AUTOSAR XML (schema 00048)
package /Eps_Repository/ActiveReturn/ActiveReturnCdp
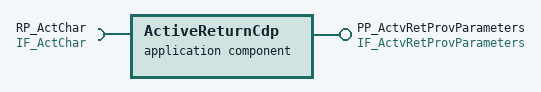
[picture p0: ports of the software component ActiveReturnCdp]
  application sw component type ActiveReturnCdp
    provide port PP_ActvRetProvParameters: provided-interface=IF_ActvRetProvParameters
    require port RP_ActChar: required-interface=IF_ActChar
    behavior IB_ActiveReturnCdp: constant-value-mapping=CSMS_ActvRetCdp, data-type-mapping=[DTMS_ActvRetCdp, DTMS_ActvRet_L_Adpr], handle-termination-and-restart=NO-SUPPORT
      13 x operation invoked event:
        OIE_ActiveReturnCdp_Prov_MaxMotTrqDepOnSteerAng: start-on-event=ActRetCdp_Prov_MaxMotTrqDepOnSteerAng, operation=PP_ActvRetProvParameters.Get_ActvRetMaxMotTrqDepOnSteerAng
        OIE_ActiveReturnCdp_Prov_MaxMotTrqDepOnVehSpd: start-on-event=ActRetCdp_Prov_MaxMotTrqDepOnVehSpd, operation=PP_ActvRetProvParameters.Get_ActvRetMaxMotTrqDepOnVehSpd
        OIE_ActiveReturnCdp_Prov_MaxMotTrq: start-on-event=ActRetCdp_Prov_MaxMotTrq, operation=PP_ActvRetProvParameters.Get_ActvRetMaxMotTrq
        OIE_ActiveReturnCdp_Prov_MaxTBT4ShtDwn: start-on-event=ActRetCdp_Prov_MaxTBT4ShtDwn, operation=PP_ActvRetProvParameters.Get_ActvRetMaxTBT4ShtDwn
        OIE_ActiveReturnCdp_Prov_NomSteerSpd: start-on-event=ActRetCdp_Prov_NomSteerSpd, operation=PP_ActvRetProvParameters.Get_ActvRetNomSteerSpd
        OIE_ActiveReturnCdp_Prov_FilFac: start-on-event=ActRetCdp_Prov_FilFac, operation=PP_ActvRetProvParameters.Get_ActvRetFilFac
        OIE_ActiveReturnCdp_Prov_MotTrqGain: start-on-event=ActRetCdp_Prov_MotTrqGain, operation=PP_ActvRetProvParameters.Get_ActvRetMotTrqGain
        OIE_ActiveReturnCdp_Prov_RetTrqFactDepOnDrvr: start-on-event=ActRetCdp_Prov_RetTrqFactDepOnDrvr, operation=PP_ActvRetProvParameters.Get_ActvRetRetTrqFactDepOnDrvr
        OIE_ActiveReturnCdp_Prov_SteerSpdFactDepOnDrvr: start-on-event=ActRetCdp_Prov_SteerSpdFactDepOnDrvr, operation=PP_ActvRetProvParameters.Get_ActvRetSteerSpdFactDepOnDrvr
        OIE_ActiveReturnCdp_Prov_SteerSpdGradAftInvld: start-on-event=ActRetCdp_Prov_SteerSpdGradAftInvld, operation=PP_ActvRetProvParameters.Get_ActvRetSteerSpdGradAftInvld
        OIE_ActiveReturnCdp_Prov_SteerSpdAmp: start-on-event=ActRetCdp_Prov_SteerSpdAmp, operation=PP_ActvRetProvParameters.Get_ActvRetSteerSpdAmp
        OIE_ActiveReturnCdp_Prov_SteerSpdFact: start-on-event=ActRetCdp_Prov_SteerSpdFact, operation=PP_ActvRetProvParameters.Get_ActvRetSteerSpdFact
        OIE_ActiveReturnCdp_Prov_MaxMotTrqAftLoadFac: start-on-event=ActRetCdp_Prov_MaxMotTrqAftLoadFac, operation=PP_ActvRetProvParameters.Get_ActvRetMaxMotTrqAftLoadFac
      13 x runnable:
        ActRetCdp_Prov_MaxMotTrqDepOnSteerAng: symbol=ActRetCdp_ProvideMaxMotorTorqueDepOnSteeringAngle
          data-receive-point-by-arguments:
            access DRP_RP_ActChar_ActChar: accessed-variable=RP_ActChar.ActChar
          6 x parameter access:
            SCPVA_MaxMotTrqDepOnSteerAngA: accessed-parameter=MaxMotTrqDepOnSteerAngA, sw-calprm-axis-set={sw-axis-index=1, sw-axis-grouped=ar-parameter=MaxMotTrqDepOnSteerAngA_AxisX}
            SCPVA_MaxMotTrqDepOnSteerAngA_AxisX: accessed-parameter=MaxMotTrqDepOnSteerAngA_AxisX
            SCPVA_MaxMotTrqDepOnSteerAngB_AxisX: accessed-parameter=MaxMotTrqDepOnSteerAngB_AxisX
            SCPVA_MaxMotTrqDepOnSteerAngC_AxisX: accessed-parameter=MaxMotTrqDepOnSteerAngC_AxisX
            SCPVA_MaxMotTrqDepOnSteerAngB: accessed-parameter=MaxMotTrqDepOnSteerAngB, sw-calprm-axis-set={sw-axis-index=1, sw-axis-grouped=ar-parameter=MaxMotTrqDepOnSteerAngB_AxisX}
            SCPVA_MaxMotTrqDepOnSteerAngC: accessed-parameter=MaxMotTrqDepOnSteerAngC, sw-calprm-axis-set={sw-axis-index=1, sw-axis-grouped=ar-parameter=MaxMotTrqDepOnSteerAngC_AxisX}
        ActRetCdp_Prov_MaxMotTrqDepOnVehSpd: symbol=ActRetCdp_ProvideMaxMotorTorqueDepOnVehSpeed
          data-receive-point-by-arguments:
            access DRP_RP_ActChar_ActChar: accessed-variable=RP_ActChar.ActChar
          6 x parameter access:
            SCPVA_MaxMotTrqDepOnVehSpdA: accessed-parameter=MaxMotTrqDepOnVehSpdA, sw-calprm-axis-set={sw-axis-index=1, sw-axis-grouped=ar-parameter=MaxMotTrqDepOnVehSpdA_AxisX}
            SCPVA_MaxMotTrqDepOnVehSpdA_AxisX: accessed-parameter=MaxMotTrqDepOnVehSpdA_AxisX
            SCPVA_MaxMotTrqDepOnVehSpdB_AxisX: accessed-parameter=MaxMotTrqDepOnVehSpdB_AxisX
            SCPVA_MaxMotTrqDepOnVehSpdC_AxisX: accessed-parameter=MaxMotTrqDepOnVehSpdC_AxisX
            SCPVA_MaxMotTrqDepOnVehSpdB: accessed-parameter=MaxMotTrqDepOnVehSpdB, sw-calprm-axis-set={sw-axis-index=1, sw-axis-grouped=ar-parameter=MaxMotTrqDepOnVehSpdB_AxisX}
            SCPVA_MaxMotTrqDepOnVehSpdC: accessed-parameter=MaxMotTrqDepOnVehSpdC, sw-calprm-axis-set={sw-axis-index=1, sw-axis-grouped=ar-parameter=MaxMotTrqDepOnVehSpdC_AxisX}
        ActRetCdp_Prov_MaxMotTrq: symbol=ActRetCdp_ProvideMaxMotorTorque
          data-receive-point-by-arguments:
            access DRP_RP_ActChar_ActChar: accessed-variable=RP_ActChar.ActChar
          parameter access SCPVA_MaxMotTrqA: accessed-parameter=MaxMotTrqA
          parameter access SCPVA_MaxMotTrqB: accessed-parameter=MaxMotTrqB
          parameter access SCPVA_MaxMotTrqC: accessed-parameter=MaxMotTrqC
        ActRetCdp_Prov_MaxTBT4ShtDwn: symbol=ActRetCdp_ProvideMaxTBT4ShutDown
          data-receive-point-by-arguments:
            access DRP_RP_ActChar_ActChar: accessed-variable=RP_ActChar.ActChar
          parameter access SCPVA_MaxTBT4ShtDwnA: accessed-parameter=MaxTBT4ShtDwnA
          parameter access SCPVA_MaxTBT4ShtDwnB: accessed-parameter=MaxTBT4ShtDwnB
          parameter access SCPVA_MaxTBT4ShtDwnC: accessed-parameter=MaxTBT4ShtDwnC
        ActRetCdp_Prov_NomSteerSpd: symbol=ActRetCdp_ProvideNominalSteeringSpeed
          data-receive-point-by-arguments:
            access DRP_RP_ActChar_ActChar: accessed-variable=RP_ActChar.ActChar
          9 x parameter access:
            SCPVA_NomSteerSpdA: accessed-parameter=NomSteerSpdA, sw-calprm-axis-set=[{sw-axis-index=1, sw-axis-grouped=ar-parameter=NomSteerSpdA_AxisX}, {sw-axis-index=2, sw-axis-grouped=ar-parameter=NomSteerSpdA_AxisY}]
            SCPVA_NomSteerSpdA_AxisX: accessed-parameter=NomSteerSpdA_AxisX
            SCPVA_NomSteerSpdA_AxisY: accessed-parameter=NomSteerSpdA_AxisY
            SCPVA_NomSteerSpdB_AxisX: accessed-parameter=NomSteerSpdB_AxisX
            SCPVA_NomSteerSpdB_AxisY: accessed-parameter=NomSteerSpdB_AxisY
            SCPVA_NomSteerSpdC_AxisX: accessed-parameter=NomSteerSpdC_AxisX
            SCPVA_NomSteerSpdC_AxisY: accessed-parameter=NomSteerSpdC_AxisY
            SCPVA_NomSteerSpdB: accessed-parameter=NomSteerSpdB, sw-calprm-axis-set=[{sw-axis-index=1, sw-axis-grouped=ar-parameter=NomSteerSpdB_AxisX}, {sw-axis-index=2, sw-axis-grouped=ar-parameter=NomSteerSpdB_AxisY}]
            SCPVA_NomSteerSpdC: accessed-parameter=NomSteerSpdC, sw-calprm-axis-set=[{sw-axis-index=1, sw-axis-grouped=ar-parameter=NomSteerSpdC_AxisX}, {sw-axis-index=2, sw-axis-grouped=ar-parameter=NomSteerSpdC_AxisY}]
        ActRetCdp_Prov_FilFac: symbol=ActRetCdp_ProvideFilterFactor
          data-receive-point-by-arguments:
            access DRP_RP_ActChar_ActChar: accessed-variable=RP_ActChar.ActChar
          parameter access SCPVA_FilFacA: accessed-parameter=FilFacA
          parameter access SCPVA_FilFacB: accessed-parameter=FilFacB
          parameter access SCPVA_FilFacC: accessed-parameter=FilFacC
        ActRetCdp_Prov_MotTrqGain: symbol=ActRetCdp_ProvideMotorTorqueGain
          data-receive-point-by-arguments:
            access DRP_RP_ActChar_ActChar: accessed-variable=RP_ActChar.ActChar
          6 x parameter access:
            SCPVA_MotTrqGainA: accessed-parameter=MotTrqGainA, sw-calprm-axis-set={sw-axis-index=1, sw-axis-grouped=ar-parameter=MotTrqGainA_AxisX}
            SCPVA_MotTrqGainA_AxisX: accessed-parameter=MotTrqGainA_AxisX
            SCPVA_MotTrqGainB_AxisX: accessed-parameter=MotTrqGainB_AxisX
            SCPVA_MotTrqGainC_AxisX: accessed-parameter=MotTrqGainC_AxisX
            SCPVA_MotTrqGainB: accessed-parameter=MotTrqGainB, sw-calprm-axis-set={sw-axis-index=1, sw-axis-grouped=ar-parameter=MotTrqGainB_AxisX}
            SCPVA_MotTrqGainC: accessed-parameter=MotTrqGainC, sw-calprm-axis-set={sw-axis-index=1, sw-axis-grouped=ar-parameter=MotTrqGainC_AxisX}
        ActRetCdp_Prov_RetTrqFactDepOnDrvr: symbol=ActRetCdp_ProvideRetTorqueFactDepOnDriver
          data-receive-point-by-arguments:
            access DRP_RP_ActChar_ActChar: accessed-variable=RP_ActChar.ActChar
          9 x parameter access:
            SCPVA_RetTrqFactDepOnDrvrA: accessed-parameter=RetTrqFactDepOnDrvrA, sw-calprm-axis-set=[{sw-axis-index=1, sw-axis-grouped=ar-parameter=RetTrqFactDepOnDrvrA_AxisX}, {sw-axis-index=2, sw-axis-grouped=ar-parameter=RetTrqFactDepOnDrvrA_AxisY}]
            SCPVA_RetTrqFactDepOnDrvrA_AxisX: accessed-parameter=RetTrqFactDepOnDrvrA_AxisX
            SCPVA_RetTrqFactDepOnDrvrA_AxisY: accessed-parameter=RetTrqFactDepOnDrvrA_AxisY
            SCPVA_RetTrqFactDepOnDrvrB_AxisX: accessed-parameter=RetTrqFactDepOnDrvrB_AxisX
            SCPVA_RetTrqFactDepOnDrvrB_AxisY: accessed-parameter=RetTrqFactDepOnDrvrB_AxisY
            SCPVA_RetTrqFactDepOnDrvrC_AxisX: accessed-parameter=RetTrqFactDepOnDrvrC_AxisX
            SCPVA_RetTrqFactDepOnDrvrC_AxisY: accessed-parameter=RetTrqFactDepOnDrvrC_AxisY
            SCPVA_RetTrqFactDepOnDrvrB: accessed-parameter=RetTrqFactDepOnDrvrB, sw-calprm-axis-set=[{sw-axis-index=1, sw-axis-grouped=ar-parameter=RetTrqFactDepOnDrvrB_AxisX}, {sw-axis-index=2, sw-axis-grouped=ar-parameter=RetTrqFactDepOnDrvrB_AxisY}]
            SCPVA_RetTrqFactDepOnDrvrC: accessed-parameter=RetTrqFactDepOnDrvrC, sw-calprm-axis-set=[{sw-axis-index=1, sw-axis-grouped=ar-parameter=RetTrqFactDepOnDrvrC_AxisX}, {sw-axis-index=2, sw-axis-grouped=ar-parameter=RetTrqFactDepOnDrvrC_AxisY}]
        ActRetCdp_Prov_SteerSpdFactDepOnDrvr: symbol=ActRetCdp_ProvideSteerSpeedFactDepOnDriver
          data-receive-point-by-arguments:
            access DRP_RP_ActChar_ActChar: accessed-variable=RP_ActChar.ActChar
          9 x parameter access:
            SCPVA_SteerSpdFactDepOnDrvrA: accessed-parameter=SteerSpdFactDepOnDrvrA, sw-calprm-axis-set=[{sw-axis-index=1, sw-axis-grouped=ar-parameter=SteerSpdFactDepOnDrvrA_AxisX}, {sw-axis-index=2, sw-axis-grouped=ar-parameter=SteerSpdFactDepOnDrvrA_AxisY}]
            SCPVA_SteerSpdFactDepOnDrvrA_AxisX: accessed-parameter=SteerSpdFactDepOnDrvrA_AxisX
            SCPVA_SteerSpdFactDepOnDrvrA_AxisY: accessed-parameter=SteerSpdFactDepOnDrvrA_AxisY
            SCPVA_SteerSpdFactDepOnDrvrB_AxisX: accessed-parameter=SteerSpdFactDepOnDrvrB_AxisX
            SCPVA_SteerSpdFactDepOnDrvrB_AxisY: accessed-parameter=SteerSpdFactDepOnDrvrB_AxisY
            SCPVA_SteerSpdFactDepOnDrvrC_AxisX: accessed-parameter=SteerSpdFactDepOnDrvrC_AxisX
            SCPVA_SteerSpdFactDepOnDrvrC_AxisY: accessed-parameter=SteerSpdFactDepOnDrvrC_AxisY
            SCPVA_SteerSpdFactDepOnDrvrB: accessed-parameter=SteerSpdFactDepOnDrvrB, sw-calprm-axis-set=[{sw-axis-index=1, sw-axis-grouped=ar-parameter=SteerSpdFactDepOnDrvrB_AxisX}, {sw-axis-index=2, sw-axis-grouped=ar-parameter=SteerSpdFactDepOnDrvrB_AxisY}]
            SCPVA_SteerSpdFactDepOnDrvrC: accessed-parameter=SteerSpdFactDepOnDrvrC, sw-calprm-axis-set=[{sw-axis-index=1, sw-axis-grouped=ar-parameter=SteerSpdFactDepOnDrvrC_AxisX}, {sw-axis-index=2, sw-axis-grouped=ar-parameter=SteerSpdFactDepOnDrvrC_AxisY}]
        ActRetCdp_Prov_SteerSpdGradAftInvld: symbol=ActRetCdp_ProvideSteerSpeedGradAfterInvalid
          data-receive-point-by-arguments:
            access DRP_RP_ActChar_ActChar: accessed-variable=RP_ActChar.ActChar
          parameter access SCPVA_SteerSpdGradAftInvldA: accessed-parameter=SteerSpdGradAftInvldA
          parameter access SCPVA_SteerSpdGradAftInvldB: accessed-parameter=SteerSpdGradAftInvldB
          parameter access SCPVA_SteerSpdGradAftInvldC: accessed-parameter=SteerSpdGradAftInvldC
        ActRetCdp_Prov_SteerSpdAmp: symbol=ActRetCdp_ProvideSteeringSpeedAmp
          data-receive-point-by-arguments:
            access DRP_RP_ActChar_ActChar: accessed-variable=RP_ActChar.ActChar
          parameter access SCPVA_SteerSpdAmpA: accessed-parameter=SteerSpdAmpA
          parameter access SCPVA_SteerSpdAmpB: accessed-parameter=SteerSpdAmpB
          parameter access SCPVA_SteerSpdAmpC: accessed-parameter=SteerSpdAmpC
        ActRetCdp_Prov_SteerSpdFact: symbol=ActRetCdp_ProvideSteeringSpeedFact
          data-receive-point-by-arguments:
            access DRP_RP_ActChar_ActChar: accessed-variable=RP_ActChar.ActChar
          parameter access SCPVA_SteerSpdFactA: accessed-parameter=SteerSpdFactA
          parameter access SCPVA_SteerSpdFactB: accessed-parameter=SteerSpdFactB
          parameter access SCPVA_SteerSpdFactC: accessed-parameter=SteerSpdFactC
        ActRetCdp_Prov_MaxMotTrqAftLoadFac: symbol=ActiveReturnCdp_ActRetCdp_Prov_MaxMotTrqAftLoadFac
          data-receive-point-by-arguments:
            access DRP_RP_ActChar_ActChar: accessed-variable=RP_ActChar.ActChar
          parameter access SCPVA_MaxMotTrqAftLoadFacA: accessed-parameter=MaxMotTrqAftLoadFacA
          parameter access SCPVA_MaxMotTrqAftLoadFacB: accessed-parameter=MaxMotTrqAftLoadFacB
          parameter access SCPVA_MaxMotTrqAftLoadFacC: accessed-parameter=MaxMotTrqAftLoadFacC
      shared-parameters:
        66 x parameter data prototype, all with sw-addr-method=CALIB, sw-calibration-access=READ-WRITE:
          MaxMotTrqDepOnSteerAngA_AxisX: unit=DegAngle, type=ADT_MaxMotTrqDepOnSteerAng_AxisX, init-value=constant-reference={short-label=ReferenceToConstant, constant=CS_MaxMotTrqDepOnSteerAng_AxisX}
          MaxMotTrqDepOnSteerAngB_AxisX: unit=DegAngle, type=ADT_MaxMotTrqDepOnSteerAng_AxisX, init-value=constant-reference={short-label=ReferenceToConstant, constant=CS_MaxMotTrqDepOnSteerAng_AxisX}
          MaxMotTrqDepOnSteerAngC_AxisX: unit=DegAngle, type=ADT_MaxMotTrqDepOnSteerAng_AxisX, init-value=constant-reference={short-label=ReferenceToConstant, constant=CS_MaxMotTrqDepOnSteerAng_AxisX}
          MaxMotTrqDepOnSteerAngA: sw-calprm-axis-set=sw-axis-grouped=ar-parameter=MaxMotTrqDepOnSteerAngA_AxisX, unit=NwtMtr, type=ADT_MaxMotTrqDepOnSteerAng, init-value=constant-reference={short-label=ReferenceToConstant, constant=CS_MaxMotTrqDepOnSteerAng}
          MaxMotTrqDepOnVehSpdA: sw-calprm-axis-set=sw-axis-grouped=ar-parameter=MaxMotTrqDepOnVehSpdA_AxisX, unit=NwtMtr, type=ADT_MaxMotTrqDepOnVehSpd, init-value=constant-reference={short-label=ReferenceToConstant, constant=CS_MaxMotTrqDepOnVehSpd}
          MaxMotTrqDepOnVehSpdA_AxisX: unit=KiloMtrPerHr, type=ADT_MaxMotTrqDepOnVehSpd_AxisX, init-value=constant-reference={short-label=ReferenceToConstant, constant=CS_MaxMotTrqDepOnVehSpd_AxisX}
          MaxMotTrqDepOnVehSpdB_AxisX: unit=KiloMtrPerHr, type=ADT_MaxMotTrqDepOnVehSpd_AxisX, init-value=constant-reference={short-label=ReferenceToConstant, constant=CS_MaxMotTrqDepOnVehSpd_AxisX}
          MaxMotTrqDepOnVehSpdC_AxisX: unit=KiloMtrPerHr, type=ADT_MaxMotTrqDepOnVehSpd_AxisX, init-value=constant-reference={short-label=ReferenceToConstant, constant=CS_MaxMotTrqDepOnVehSpd_AxisX}
          MotTrqGainA: sw-calprm-axis-set=sw-axis-grouped=ar-parameter=MotTrqGainA_AxisX, unit=NoUnit, type=ADT_MotTrqGain, init-value=constant-reference={short-label=ReferenceToConstant, constant=CS_MotTrqGain}
          MotTrqGainA_AxisX: unit=KiloMtrPerHr, type=ADT_MotTrqGain_AxisX, init-value=constant-reference={short-label=ReferenceToConstant, constant=CS_MotTrqGain_AxisX}
          MotTrqGainB_AxisX: unit=KiloMtrPerHr, type=ADT_MotTrqGain_AxisX, init-value=constant-reference={short-label=ReferenceToConstant, constant=CS_MotTrqGain_AxisX}
          MotTrqGainC_AxisX: unit=KiloMtrPerHr, type=ADT_MotTrqGain_AxisX, init-value=constant-reference={short-label=ReferenceToConstant, constant=CS_MotTrqGain_AxisX}
          RetTrqFactDepOnDrvrA: sw-calprm-axis-set=[{sw-axis-index=1, sw-axis-grouped=ar-parameter=RetTrqFactDepOnDrvrA_AxisX}, {sw-axis-index=2, sw-axis-grouped=ar-parameter=RetTrqFactDepOnDrvrA_AxisY}], unit=NoUnit, type=ADT_RetTrqFactDepOnDrvr, init-value=constant-reference={short-label=ReferenceToConstant, constant=CS_RetTrqFactDepOnDrvr}
          RetTrqFactDepOnDrvrA_AxisX: unit=NwtMtr, type=ADT_RetTrqFactDepOnDrvr_AxisX, init-value=constant-reference={short-label=ReferenceToConstant, constant=CS_RetTrqFactDepOnDrvr_AxisX}
          RetTrqFactDepOnDrvrB_AxisX: unit=NwtMtr, type=ADT_RetTrqFactDepOnDrvr_AxisX, init-value=constant-reference={short-label=ReferenceToConstant, constant=CS_RetTrqFactDepOnDrvr_AxisX}
          RetTrqFactDepOnDrvrC_AxisX: unit=NwtMtr, type=ADT_RetTrqFactDepOnDrvr_AxisX, init-value=constant-reference={short-label=ReferenceToConstant, constant=CS_RetTrqFactDepOnDrvr_AxisX}
          RetTrqFactDepOnDrvrA_AxisY: unit=KiloMtrPerHr, type=ADT_RetTrqFactDepOnDrvr_AxisY, init-value=constant-reference={short-label=ReferenceToConstant, constant=CS_RetTrqFactDepOnDrvr_AxisY}
          RetTrqFactDepOnDrvrB_AxisY: unit=KiloMtrPerHr, type=ADT_RetTrqFactDepOnDrvr_AxisY, init-value=constant-reference={short-label=ReferenceToConstant, constant=CS_RetTrqFactDepOnDrvr_AxisY}
          RetTrqFactDepOnDrvrC_AxisY: unit=KiloMtrPerHr, type=ADT_RetTrqFactDepOnDrvr_AxisY, init-value=constant-reference={short-label=ReferenceToConstant, constant=CS_RetTrqFactDepOnDrvr_AxisY}
          SteerSpdFactDepOnDrvrA: sw-calprm-axis-set=[{sw-axis-index=1, sw-axis-grouped=ar-parameter=SteerSpdFactDepOnDrvrA_AxisX}, {sw-axis-index=2, sw-axis-grouped=ar-parameter=SteerSpdFactDepOnDrvrA_AxisY}], unit=NoUnit, type=ADT_SteerSpdFactDepOnDrvr, init-value=constant-reference={short-label=ReferenceToConstant, constant=CS_SteerSpdFactDepOnDrvr}
          SteerSpdFactDepOnDrvrA_AxisX: unit=NwtMtr, type=ADT_SteerSpdFactDepOnDrvr_AxisX, init-value=constant-reference={short-label=ReferenceToConstant, constant=CS_SteerSpdFactDepOnDrvr_AxisX}
          SteerSpdFactDepOnDrvrB_AxisX: unit=NwtMtr, type=ADT_SteerSpdFactDepOnDrvr_AxisX, init-value=constant-reference={short-label=ReferenceToConstant, constant=CS_SteerSpdFactDepOnDrvr_AxisX}
          SteerSpdFactDepOnDrvrC_AxisX: unit=NwtMtr, type=ADT_SteerSpdFactDepOnDrvr_AxisX, init-value=constant-reference={short-label=ReferenceToConstant, constant=CS_SteerSpdFactDepOnDrvr_AxisX}
          SteerSpdFactDepOnDrvrA_AxisY: unit=KiloMtrPerHr, type=ADT_SteerSpdFactDepOnDrvr_AxisY, init-value=constant-reference={short-label=ReferenceToConstant, constant=CS_SteerSpdFactDepOnDrvr_AxisY}
          SteerSpdFactDepOnDrvrB_AxisY: unit=KiloMtrPerHr, type=ADT_SteerSpdFactDepOnDrvr_AxisY, init-value=constant-reference={short-label=ReferenceToConstant, constant=CS_SteerSpdFactDepOnDrvr_AxisY}
          SteerSpdFactDepOnDrvrC_AxisY: unit=KiloMtrPerHr, type=ADT_SteerSpdFactDepOnDrvr_AxisY, init-value=constant-reference={short-label=ReferenceToConstant, constant=CS_SteerSpdFactDepOnDrvr_AxisY}
          MaxMotTrqA: unit=NwtMtr, type=ADT_MaxMotTrq, init-value=constant-reference={short-label=ReferenceToConstant, constant=CS_MaxMotTrq}
          MaxTBT4ShtDwnA: unit=NwtMtr, type=ADT_MaxTBT4ShtDwn, init-value=constant-reference={short-label=ReferenceToConstant, constant=CS_MaxTBT4ShtDwn}
          FilFacA: unit=NoUnit, type=ADT_FilFac, init-value=constant-reference={short-label=ReferenceToConstant, constant=CS_FilFac}
          SteerSpdGradAftInvldA: unit=NoUnit, type=ADT_SteerSpdGradAftInvld, init-value=constant-reference={short-label=ReferenceToConstant, constant=CS_SteerSpdGradAftInvld}
          SteerSpdFactA: unit=NoUnit, type=ADT_SteerSpdFact, init-value=constant-reference={short-label=ReferenceToConstant, constant=CS_SteerSpdFact}
          NomSteerSpdA_AxisX: unit=KiloMtrPerHr, type=ADT_NomSteerSpd_AxisX, init-value=constant-reference={short-label=ReferenceToConstant, constant=CS_NomSteerSpd_AxisX}
          NomSteerSpdB_AxisX: unit=KiloMtrPerHr, type=ADT_NomSteerSpd_AxisX, init-value=constant-reference={short-label=ReferenceToConstant, constant=CS_NomSteerSpd_AxisX}
          NomSteerSpdC_AxisX: unit=KiloMtrPerHr, type=ADT_NomSteerSpd_AxisX, init-value=constant-reference={short-label=ReferenceToConstant, constant=CS_NomSteerSpd_AxisX}
          NomSteerSpdA_AxisY: unit=DegAngle, type=ADT_NomSteerSpd_AxisY, init-value=constant-reference={short-label=ReferenceToConstant, constant=CS_NomSteerSpd_AxisY}
          NomSteerSpdB_AxisY: unit=DegAngle, type=ADT_NomSteerSpd_AxisY, init-value=constant-reference={short-label=ReferenceToConstant, constant=CS_NomSteerSpd_AxisY}
          NomSteerSpdC_AxisY: unit=DegAngle, type=ADT_NomSteerSpd_AxisY, init-value=constant-reference={short-label=ReferenceToConstant, constant=CS_NomSteerSpd_AxisY}
          NomSteerSpdA: sw-calprm-axis-set=[{sw-axis-index=1, sw-axis-grouped=ar-parameter=NomSteerSpdA_AxisX}, {sw-axis-index=2, sw-axis-grouped=ar-parameter=NomSteerSpdA_AxisY}], unit=NoUnit, type=ADT_NomSteerSpd, init-value=constant-reference={short-label=ReferenceToConstant, constant=CS_NomSteerSpd}
          SteerSpdAmpA: unit=NoUnit, type=ADT_SteerSpdAmp, init-value=constant-reference={short-label=ReferenceToConstant, constant=CS_SteerSpdAmp}
          MaxMotTrqB: unit=NwtMtr, type=ADT_MaxMotTrq, init-value=constant-reference={short-label=ReferenceToConstant, constant=CS_MaxMotTrq}
          MaxMotTrqC: unit=NwtMtr, type=ADT_MaxMotTrq, init-value=constant-reference={short-label=ReferenceToConstant, constant=CS_MaxMotTrq}
          MaxMotTrqDepOnSteerAngB: sw-calprm-axis-set=sw-axis-grouped=ar-parameter=MaxMotTrqDepOnSteerAngB_AxisX, unit=NwtMtr, type=ADT_MaxMotTrqDepOnSteerAng, init-value=constant-reference={short-label=ReferenceToConstant, constant=CS_MaxMotTrqDepOnSteerAng}
          MaxMotTrqDepOnVehSpdB: sw-calprm-axis-set=sw-axis-grouped=ar-parameter=MaxMotTrqDepOnVehSpdB_AxisX, unit=NwtMtr, type=ADT_MaxMotTrqDepOnVehSpd, init-value=constant-reference={short-label=ReferenceToConstant, constant=CS_MaxMotTrqDepOnVehSpd}
          MaxTBT4ShtDwnB: unit=NwtMtr, type=ADT_MaxTBT4ShtDwn, init-value=constant-reference={short-label=ReferenceToConstant, constant=CS_MaxTBT4ShtDwn}
          MaxMotTrqDepOnSteerAngC: sw-calprm-axis-set=sw-axis-grouped=ar-parameter=MaxMotTrqDepOnSteerAngC_AxisX, unit=NwtMtr, type=ADT_MaxMotTrqDepOnSteerAng, init-value=constant-reference={short-label=ReferenceToConstant, constant=CS_MaxMotTrqDepOnSteerAng}
          MaxMotTrqDepOnVehSpdC: sw-calprm-axis-set=sw-axis-grouped=ar-parameter=MaxMotTrqDepOnVehSpdC_AxisX, unit=NwtMtr, type=ADT_MaxMotTrqDepOnVehSpd, init-value=constant-reference={short-label=ReferenceToConstant, constant=CS_MaxMotTrqDepOnVehSpd}
          MaxTBT4ShtDwnC: unit=NwtMtr, type=ADT_MaxTBT4ShtDwn, init-value=constant-reference={short-label=ReferenceToConstant, constant=CS_MaxTBT4ShtDwn}
          NomSteerSpdB: sw-calprm-axis-set=[{sw-axis-index=1, sw-axis-grouped=ar-parameter=NomSteerSpdB_AxisX}, {sw-axis-index=2, sw-axis-grouped=ar-parameter=NomSteerSpdB_AxisY}], unit=NoUnit, type=ADT_NomSteerSpd, init-value=constant-reference={short-label=ReferenceToConstant, constant=CS_NomSteerSpd}
          NomSteerSpdC: sw-calprm-axis-set=[{sw-axis-index=1, sw-axis-grouped=ar-parameter=NomSteerSpdC_AxisX}, {sw-axis-index=2, sw-axis-grouped=ar-parameter=NomSteerSpdC_AxisY}], unit=NoUnit, type=ADT_NomSteerSpd, init-value=constant-reference={short-label=ReferenceToConstant, constant=CS_NomSteerSpd}
          FilFacB: unit=NoUnit, type=ADT_FilFac, init-value=constant-reference={short-label=ReferenceToConstant, constant=CS_FilFac}
          FilFacC: unit=NoUnit, type=ADT_FilFac, init-value=constant-reference={short-label=ReferenceToConstant, constant=CS_FilFac}
          MotTrqGainB: sw-calprm-axis-set=sw-axis-grouped=ar-parameter=MotTrqGainB_AxisX, unit=NoUnit, type=ADT_MotTrqGain, init-value=constant-reference={short-label=ReferenceToConstant, constant=CS_MotTrqGain}
          MotTrqGainC: sw-calprm-axis-set=sw-axis-grouped=ar-parameter=MotTrqGainC_AxisX, unit=NoUnit, type=ADT_MotTrqGain, init-value=constant-reference={short-label=ReferenceToConstant, constant=CS_MotTrqGain}
          RetTrqFactDepOnDrvrB: sw-calprm-axis-set=[{sw-axis-index=1, sw-axis-grouped=ar-parameter=RetTrqFactDepOnDrvrB_AxisX}, {sw-axis-index=2, sw-axis-grouped=ar-parameter=RetTrqFactDepOnDrvrB_AxisY}], unit=NoUnit, type=ADT_RetTrqFactDepOnDrvr, init-value=constant-reference={short-label=ReferenceToConstant, constant=CS_RetTrqFactDepOnDrvr}
          RetTrqFactDepOnDrvrC: sw-calprm-axis-set=[{sw-axis-index=1, sw-axis-grouped=ar-parameter=RetTrqFactDepOnDrvrC_AxisX}, {sw-axis-index=2, sw-axis-grouped=ar-parameter=RetTrqFactDepOnDrvrC_AxisY}], unit=NoUnit, type=ADT_RetTrqFactDepOnDrvr, init-value=constant-reference={short-label=ReferenceToConstant, constant=CS_RetTrqFactDepOnDrvr}
          SteerSpdAmpB: unit=NoUnit, type=ADT_SteerSpdAmp, init-value=constant-reference={short-label=ReferenceToConstant, constant=CS_SteerSpdAmp}
          SteerSpdAmpC: unit=NoUnit, type=ADT_SteerSpdAmp, init-value=constant-reference={short-label=ReferenceToConstant, constant=CS_SteerSpdAmp}
          SteerSpdFactB: unit=NoUnit, type=ADT_SteerSpdFact, init-value=constant-reference={short-label=ReferenceToConstant, constant=CS_SteerSpdFact}
          SteerSpdFactC: unit=NoUnit, type=ADT_SteerSpdFact, init-value=constant-reference={short-label=ReferenceToConstant, constant=CS_SteerSpdFact}
          SteerSpdFactDepOnDrvrB: sw-calprm-axis-set=[{sw-axis-index=1, sw-axis-grouped=ar-parameter=SteerSpdFactDepOnDrvrB_AxisX}, {sw-axis-index=2, sw-axis-grouped=ar-parameter=SteerSpdFactDepOnDrvrB_AxisY}], unit=NoUnit, type=ADT_SteerSpdFactDepOnDrvr, init-value=constant-reference={short-label=ReferenceToConstant, constant=CS_SteerSpdFactDepOnDrvr}
          SteerSpdFactDepOnDrvrC: sw-calprm-axis-set=[{sw-axis-index=1, sw-axis-grouped=ar-parameter=SteerSpdFactDepOnDrvrC_AxisX}, {sw-axis-index=2, sw-axis-grouped=ar-parameter=SteerSpdFactDepOnDrvrC_AxisY}], unit=NoUnit, type=ADT_SteerSpdFactDepOnDrvr, init-value=constant-reference={short-label=ReferenceToConstant, constant=CS_SteerSpdFactDepOnDrvr}
          SteerSpdGradAftInvldB: unit=NoUnit, type=ADT_SteerSpdGradAftInvld, init-value=constant-reference={short-label=ReferenceToConstant, constant=CS_SteerSpdGradAftInvld}
          SteerSpdGradAftInvldC: unit=NoUnit, type=ADT_SteerSpdGradAftInvld, init-value=constant-reference={short-label=ReferenceToConstant, constant=CS_SteerSpdGradAftInvld}
          MaxMotTrqAftLoadFacA: unit=NwtMtr, type=ADT_MaxMotTrqAftLoadFac, init-value=constant-reference={short-label=ReferenceToConstant, constant=CS_MaxMotTrqAftLoadFac}
          MaxMotTrqAftLoadFacB: unit=NwtMtr, type=ADT_MaxMotTrqAftLoadFac, init-value=constant-reference={short-label=ReferenceToConstant, constant=CS_MaxMotTrqAftLoadFac}
          MaxMotTrqAftLoadFacC: unit=NwtMtr, type=ADT_MaxMotTrqAftLoadFac, init-value=constant-reference={short-label=ReferenceToConstant, constant=CS_MaxMotTrqAftLoadFac}
package /Eps_Repository/ActiveReturn/ActiveReturnCdp/ApplicationDataTypes
  35 x app type:
    ADT_NomSteerSpd: category=MAP, sw-addr-method=CALIB, sw-calibration-access=READ-WRITE, sw-calprm-axis-set=[{sw-axis-index=1, category=COM_AXIS, sw-axis-grouped=ADT_NomSteerSpd_AxisX}, {sw-axis-index=2, category=COM_AXIS, sw-axis-grouped=ADT_NomSteerSpd_AxisY}], compu-method=CM_SAS_8, range phys 0..1500, raw 0..12000, sw-record-layout=SwRecordLayout_Map_uint16
    ADT_NomSteerSpd_AxisX: category=COM_AXIS, sw-calibration-access=READ-WRITE, sw-calprm-axis-set={sw-axis-index=1, sw-axis-individual={input-variable-type=ADT_AbsAvgVehSpd, compu-method=CM_VFZHIGH, sw-max-axis-points=6, sw-min-axis-points=6, range phys 0..500, raw 0..32000}}, sw-record-layout=SwRecordLayout_Axis_uint16
    ADT_NomSteerSpd_AxisY: category=COM_AXIS, sw-calibration-access=READ-WRITE, sw-calprm-axis-set={sw-axis-index=2, sw-axis-individual={input-variable-type=ADT_AbsSteerAng, compu-method=CM_SA_10, sw-max-axis-points=13, sw-min-axis-points=13, range phys 0..1000, raw 0..10000}}, sw-record-layout=SwRecordLayout_Axis_uint16
    ADT_MaxTBT4ShtDwn: category=VALUE, compu-method=CM_TBT_RSH4, range phys 0..15, raw 0..240
    ADT_FilFac: category=VALUE, compu-method=CM_RIGHTSH10NP, range phys 0.01..1, raw 0..1024
    ADT_FilFac_Val: category=VALUE, compu-method=CM_RIGHTSH10NP, range phys 0.01..1, raw 0..1024
    ADT_MaxTBT4ShtDwn_Val: category=VALUE, compu-method=CM_TBT_RSH4, range phys 0..15, raw 0..240
    ADT_MaxMotTrqDepOnSteerAng_AxisX: category=COM_AXIS, sw-calibration-access=READ-WRITE, sw-calprm-axis-set={sw-axis-index=1, sw-axis-individual={input-variable-type=ADT_AbsSteerAng, compu-method=CM_SA_10, sw-max-axis-points=5, sw-min-axis-points=5, range phys 0..1000, raw 0..10000}}, sw-record-layout=SwRecordLayout_Axis_uint16
    ADT_MaxMotTrqDepOnSteerAng: category=CURVE, sw-addr-method=CALIB, sw-calibration-access=READ-WRITE, sw-calprm-axis-set={sw-axis-index=1, category=COM_AXIS, sw-axis-grouped=ADT_MaxMotTrqDepOnSteerAng_AxisX}, compu-method=CM_MMOT, range phys 0..3, raw 0..3072, sw-record-layout=SwRecordLayout_Curve_uint16
    ADT_MaxMotTrqDepOnVehSpd_Val: category=VALUE, compu-method=CM_MMOT, range phys 0..3, raw 0..3072
    ADT_NomSteerSpd_Val: category=VALUE, compu-method=CM_SAS_8, range phys 0..1500, raw 0..12000
    ADT_RetTrqFactDepOnDrvr_Val: category=VALUE, compu-method=CM_RIGHTSH10NP, range phys 0..1, raw 0..1024
    ADT_SteerSpdGradAftInvld: category=VALUE, compu-method=CM_RIGHTSH15NP, range phys 0..1, raw 0..32768
    ADT_SteerSpdGradAftInvld_Val: category=VALUE, compu-method=CM_RIGHTSH15NP, range phys 0..1, raw 0..32768
    ADT_SteerSpdAmp: category=VALUE, compu-method=CM_ARFACT, range phys 0..0.02, raw 0..328
    ADT_SteerSpdAmp_Val: category=VALUE, compu-method=CM_ARFACT, range phys 0..0.02, raw 0..328
    ADT_SteerSpdFact: category=VALUE, compu-method=CM_RIGHTSH7NP, range phys 0..1.5, raw 0..192
    ADT_SteerSpdFact_Val: category=VALUE, compu-method=CM_RIGHTSH7NP, range phys 0..1.5, raw 0..192
    ADT_MaxMotTrqDepOnVehSpd_AxisX: category=COM_AXIS, sw-calibration-access=READ-WRITE, sw-calprm-axis-set={sw-axis-index=1, sw-axis-individual={input-variable-type=ADT_AbsMaxSafeVehSpd, compu-method=CM_VFZHIGH, sw-max-axis-points=5, sw-min-axis-points=5, range phys 0..500, raw 0..32000}}, sw-record-layout=SwRecordLayout_Axis_uint16
    ADT_MaxMotTrqDepOnVehSpd: category=CURVE, sw-addr-method=CALIB, sw-calibration-access=READ-WRITE, sw-calprm-axis-set={sw-axis-index=1, category=COM_AXIS, sw-axis-grouped=ADT_MaxMotTrqDepOnVehSpd_AxisX}, compu-method=CM_MMOT, range phys 0..3, raw 0..3072, sw-record-layout=SwRecordLayout_Curve_uint16
    ADT_MaxMotTrqDepOnSteerAng_Val: category=VALUE, compu-method=CM_MMOT, range phys 0..3, raw 0..3072
    ADT_MotTrqGain_Val: category=VALUE, compu-method=CM_RIGHTSH10NP, range phys 0..3, raw 0..3072
    ADT_MotTrqGain: category=CURVE, sw-addr-method=CALIB, sw-calibration-access=READ-WRITE, sw-calprm-axis-set={sw-axis-index=1, category=COM_AXIS, sw-axis-grouped=ADT_MotTrqGain_AxisX}, compu-method=CM_RIGHTSH10NP, range phys 0..3, raw 0..3072, sw-record-layout=SwRecordLayout_Curve_uint16
    ADT_MotTrqGain_AxisX: category=COM_AXIS, sw-calibration-access=READ-WRITE, sw-calprm-axis-set={sw-axis-index=1, sw-axis-individual={input-variable-type=ADT_AbsAvgVehSpd, compu-method=CM_VFZHIGH, sw-max-axis-points=6, sw-min-axis-points=6, range phys 0..250, raw 0..16000}}, sw-record-layout=SwRecordLayout_Axis_uint16
    ADT_RetTrqFactDepOnDrvr: category=MAP, sw-addr-method=CALIB, sw-calibration-access=READ-WRITE, sw-calprm-axis-set=[{sw-axis-index=1, category=COM_AXIS, sw-axis-grouped=ADT_RetTrqFactDepOnDrvr_AxisX}, {sw-axis-index=2, category=COM_AXIS, sw-axis-grouped=ADT_RetTrqFactDepOnDrvr_AxisY}], compu-method=CM_RIGHTSH10NP, range phys 0..1, raw 0..1024, sw-record-layout=SwRecordLayout_Map_uint16
    ADT_RetTrqFactDepOnDrvr_AxisX: category=COM_AXIS, sw-calibration-access=READ-WRITE, sw-calprm-axis-set={sw-axis-index=1, sw-axis-individual={input-variable-type=ADT_AbsDrvrTrq, compu-method=CM_TBTHIGH, sw-max-axis-points=6, sw-min-axis-points=6, range phys 0..25, raw 0..25600}}, sw-record-layout=SwRecordLayout_Axis_uint16
    ADT_RetTrqFactDepOnDrvr_AxisY: category=COM_AXIS, sw-calibration-access=READ-WRITE, sw-calprm-axis-set={sw-axis-index=2, sw-axis-individual={input-variable-type=ADT_AbsAvgVehSpd, compu-method=CM_VFZHIGH, sw-max-axis-points=3, sw-min-axis-points=3, range phys 0..500, raw 0..32000}}, sw-record-layout=SwRecordLayout_Axis_uint16
    ADT_SteerSpdFactDepOnDrvr: category=MAP, sw-addr-method=CALIB, sw-calibration-access=READ-WRITE, sw-calprm-axis-set=[{sw-axis-index=1, category=COM_AXIS, sw-axis-grouped=ADT_SteerSpdFactDepOnDrvr_AxisX}, {sw-axis-index=2, category=COM_AXIS, sw-axis-grouped=ADT_SteerSpdFactDepOnDrvr_AxisY}], compu-method=CM_RIGHTSH10NP, range phys 0..1, raw 0..1024, sw-record-layout=SwRecordLayout_Map_uint16
    ADT_SteerSpdFactDepOnDrvr_AxisX: category=COM_AXIS, sw-calibration-access=READ-WRITE, sw-calprm-axis-set={sw-axis-index=1, sw-axis-individual={input-variable-type=ADT_AbsDrvrTrq, compu-method=CM_TBTHIGH, sw-max-axis-points=6, sw-min-axis-points=6, range phys 0..25, raw 0..25600}}, sw-record-layout=SwRecordLayout_Axis_uint16
    ADT_SteerSpdFactDepOnDrvr_AxisY: category=COM_AXIS, sw-calibration-access=READ-WRITE, sw-calprm-axis-set={sw-axis-index=2, sw-axis-individual={input-variable-type=ADT_AbsAvgVehSpd, compu-method=CM_VFZHIGH, sw-max-axis-points=3, sw-min-axis-points=3, range phys 0..500, raw 0..32000}}, sw-record-layout=SwRecordLayout_Axis_uint16
    ADT_SteerSpdFactDepOnDrvr_Val: category=VALUE, compu-method=CM_RIGHTSH10NP, range phys 0..1, raw 0..1024
    ADT_MaxMotTrq: category=VALUE, compu-method=CM_MMOT_RSH6, range phys 0..3, raw 0..192
    ADT_MaxMotTrq_Val: category=VALUE, compu-method=CM_MMOT_RSH6, range phys 0..3, raw 0..192
    ADT_MaxMotTrqAftLoadFac: category=VALUE, compu-method=CM_MMOT_RSH6, range phys 0..3, raw 0..192
    ADT_MaxMotTrqAftLoadFac_Val: category=VALUE, compu-method=CM_MMOT_RSH6, range phys 0..3, raw 0..192
package /Eps_Repository/ActiveReturn/ActiveReturnCdp/DataTypeMappingSets
  data type mapping set DTMS_ActvRetCdp
    data-type-maps:
      application-data-type=ADT_SteerSpdGradAftInvld, implementation-data-type=IDT_SteerSpdGradAftInvld
      application-data-type=ADT_MaxMotTrqDepOnVehSpd_Val, implementation-data-type=uint16
      application-data-type=ADT_NomSteerSpd_Val, implementation-data-type=uint16
      application-data-type=ADT_RetTrqFactDepOnDrvr_Val, implementation-data-type=uint16
      application-data-type=ADT_MaxMotTrqDepOnSteerAng, implementation-data-type=IDT_MaxMotTrqDepOnSteerAng
      application-data-type=ADT_MaxMotTrqDepOnSteerAng_AxisX, implementation-data-type=IDT_MaxMotTrqDepOnSteerAng_AxisX
      application-data-type=ADT_MaxMotTrqDepOnVehSpd, implementation-data-type=IDT_MaxMotTrqDepOnVehSpd
      application-data-type=ADT_MaxMotTrqDepOnVehSpd_AxisX, implementation-data-type=IDT_MaxMotTrqDepOnVehSpd_AxisX
      application-data-type=ADT_MaxMotTrqDepOnSteerAng_Val, implementation-data-type=uint16
      application-data-type=ADT_MotTrqGain_Val, implementation-data-type=uint16
      application-data-type=ADT_MotTrqGain, implementation-data-type=IDT_MotTrqGain_Crv
      application-data-type=ADT_MotTrqGain_AxisX, implementation-data-type=IDT_MotTrqGain_AxisX
      application-data-type=ADT_RetTrqFactDepOnDrvr_Val, implementation-data-type=uint16
      application-data-type=ADT_RetTrqFactDepOnDrvr, implementation-data-type=IDT_RetTrqFactDepOnDrvr
      application-data-type=ADT_RetTrqFactDepOnDrvr_AxisX, implementation-data-type=IDT_RetTrqFactDepOnDrvr_AxisX
      application-data-type=ADT_SteerSpdFactDepOnDrvr_Val, implementation-data-type=uint16
      application-data-type=ADT_SteerSpdFactDepOnDrvr, implementation-data-type=IDT_SteerSpdFactDepOnDrvr
      application-data-type=ADT_SteerSpdFactDepOnDrvr_AxisX, implementation-data-type=IDT_SteerSpdFactDepOnDrvr_AxisX
      application-data-type=ADT_MaxMotTrq_Val, implementation-data-type=uint8
      application-data-type=ADT_MaxMotTrq, implementation-data-type=IDT_MaxMotTrq
      application-data-type=ADT_MaxTBT4ShtDwn_Val, implementation-data-type=uint8
      application-data-type=ADT_MaxTBT4ShtDwn, implementation-data-type=IDT_MaxTBT4ShtDwn
      application-data-type=ADT_FilFac_Val, implementation-data-type=uint16
      application-data-type=ADT_FilFac, implementation-data-type=IDT_FilFac
      application-data-type=ADT_SteerSpdGradAftInvld_Val, implementation-data-type=uint16
      application-data-type=ADT_SteerSpdGradAftInvld, implementation-data-type=IDT_SteerSpdGradAftInvld
      application-data-type=ADT_SteerSpdAmp_Val, implementation-data-type=uint16
      application-data-type=ADT_SteerSpdAmp, implementation-data-type=IDT_SteerSpdAmp
      application-data-type=ADT_SteerSpdFact_Val, implementation-data-type=uint8
      application-data-type=ADT_SteerSpdFact, implementation-data-type=IDT_SteerSpdFact
      application-data-type=ADT_NomSteerSpd, implementation-data-type=IDT_NomSteerSpd
      application-data-type=ADT_NomSteerSpd_AxisX, implementation-data-type=IDT_NomSteerSpd_AxisX
      application-data-type=ADT_NomSteerSpd_AxisY, implementation-data-type=IDT_NomSteerSpd_AxisY
      application-data-type=ADT_RetTrqFactDepOnDrvr_AxisY, implementation-data-type=IDT_RetTrqFactDepOnDrvr_AxisY
      application-data-type=ADT_SteerSpdFactDepOnDrvr_AxisY, implementation-data-type=IDT_SteerSpdFactDepOnDrvr_AxisY
      application-data-type=ADT_MaxMotTrqAftLoadFac, implementation-data-type=IDT_MaxMotTrqAftLoadFac
      application-data-type=ADT_MaxMotTrqAftLoadFac_Val, implementation-data-type=uint8
package /Eps_Repository/ActiveReturn/ActiveReturnCdp/ImplementationDataTypes
  22 x impl type:
    IDT_MaxMotTrq: range phys 0..3, raw 0..192, implementation-data-type=uint8
    IDT_MaxMotTrqDepOnSteerAng_AxisX: category=ARRAY
      element IDT_Axsis_ELEMENT: array-size=5, array-size-semantics=FIXED-SIZE, implementation-data-type=uint16
    IDT_MaxMotTrqDepOnSteerAng: category=ARRAY
      element IDT_Curve_ELEMENT: array-size=5, array-size-semantics=FIXED-SIZE, implementation-data-type=uint16
    IDT_MaxTBT4ShtDwn: range phys 0..15, raw 0..240, implementation-data-type=uint8
    IDT_FilFac: range phys 0.01..1, raw 0..1024, implementation-data-type=uint16
    IDT_NomSteerSpd: category=ARRAY
      element IDT_Map_ELEMENT: category=ARRAY, array-size=6, array-size-semantics=FIXED-SIZE
        element Type_Axsis: array-size=13, array-size-semantics=FIXED-SIZE, implementation-data-type=uint16
    IDT_NomSteerSpd_AxisX: category=ARRAY
      element IDT_Axsis_ELEMENT: array-size=6, array-size-semantics=FIXED-SIZE, implementation-data-type=uint16
    IDT_NomSteerSpd_AxisY: category=ARRAY
      element IDT_Axsis_ELEMENT: array-size=13, array-size-semantics=FIXED-SIZE, implementation-data-type=uint16
    IDT_SteerSpdGradAftInvld: range phys 0..1, raw 0..32768, implementation-data-type=uint16
    IDT_SteerSpdAmp: range phys 0..0.02, raw 0..328, implementation-data-type=uint16
    IDT_SteerSpdFact: range phys 0..1.5, raw 0..192, implementation-data-type=uint8
    IDT_MaxMotTrqDepOnVehSpd: category=ARRAY
      element IDT_Curve_ELEMENT: array-size=5, array-size-semantics=FIXED-SIZE, implementation-data-type=uint16
    IDT_MaxMotTrqDepOnVehSpd_AxisX: category=ARRAY
      element IDT_Axsis_ELEMENT: array-size=5, array-size-semantics=FIXED-SIZE, implementation-data-type=uint16
    IDT_MotTrqGain_Crv: category=ARRAY
      element IDT_Curve_ELEMENT: array-size=6, array-size-semantics=FIXED-SIZE, implementation-data-type=uint16
    IDT_MotTrqGain_AxisX: category=ARRAY
      element IDT_Axsis_ELEMENT: array-size=6, array-size-semantics=FIXED-SIZE, implementation-data-type=uint16
    IDT_RetTrqFactDepOnDrvr: category=ARRAY
      element IDT_Map_ELEMENT: category=ARRAY, array-size=6, array-size-semantics=FIXED-SIZE
        element Type_Axsis: array-size=3, array-size-semantics=FIXED-SIZE, implementation-data-type=uint16
    IDT_RetTrqFactDepOnDrvr_AxisX: category=ARRAY
      element IDT_Axsis_ELEMENT: array-size=6, array-size-semantics=FIXED-SIZE, implementation-data-type=uint16
    IDT_RetTrqFactDepOnDrvr_AxisY: category=ARRAY
      element IDT_Axsis_ELEMENT: array-size=3, array-size-semantics=FIXED-SIZE, implementation-data-type=uint16
    IDT_SteerSpdFactDepOnDrvr: category=ARRAY
      element IDT_Map_ELEMENT: category=ARRAY, array-size=6, array-size-semantics=FIXED-SIZE
        element Type_Axsis: array-size=3, array-size-semantics=FIXED-SIZE, implementation-data-type=uint16
    IDT_SteerSpdFactDepOnDrvr_AxisX: category=ARRAY
      element IDT_Axsis_ELEMENT: array-size=6, array-size-semantics=FIXED-SIZE, implementation-data-type=uint16
    IDT_SteerSpdFactDepOnDrvr_AxisY: category=ARRAY
      element IDT_Axsis_ELEMENT: array-size=3, array-size-semantics=FIXED-SIZE, implementation-data-type=uint16
    IDT_MaxMotTrqAftLoadFac: range phys 0..3, raw 0..192, implementation-data-type=uint8
package /Eps_Repository/ActiveReturn/ActiveReturnCdp/Interfaces
  client server interface IF_ActvRetProvParameters
    13 x operation:
      Get_ActvRetMaxMotTrqDepOnSteerAng
        arg MaxMotTrqDepOnSteerAng_Val: type=ADT_MaxMotTrqDepOnSteerAng_Val, direction=OUT, server-argument-impl-policy=USE-ARGUMENT-TYPE
        arg AbsSteerAng: type=ADT_AbsSteerAng, direction=IN, server-argument-impl-policy=USE-ARGUMENT-TYPE
      Get_ActvRetMaxMotTrqDepOnVehSpd
        arg MaxMotTrqDepOnVehSpd_Val: type=ADT_MaxMotTrqDepOnVehSpd_Val, direction=OUT, server-argument-impl-policy=USE-ARGUMENT-TYPE
        arg AbsMaxSafeVehSpd: type=ADT_AbsMaxSafeVehSpd, direction=IN, server-argument-impl-policy=USE-ARGUMENT-TYPE
      Get_ActvRetMaxMotTrq
        arg MaxMotTrq_Val: type=ADT_MaxMotTrq_Val, direction=OUT, server-argument-impl-policy=USE-ARGUMENT-TYPE
      Get_ActvRetMaxTBT4ShtDwn
        arg MaxTBT4ShtDwn_Val: type=ADT_MaxTBT4ShtDwn_Val, direction=OUT, server-argument-impl-policy=USE-ARGUMENT-TYPE
      Get_ActvRetNomSteerSpd
        arg NomSteerSpd_Val: type=ADT_NomSteerSpd_Val, direction=OUT, server-argument-impl-policy=USE-ARGUMENT-TYPE
        arg AbsAvgVehSpd: type=ADT_AbsAvgVehSpd, direction=IN, server-argument-impl-policy=USE-ARGUMENT-TYPE
        arg AbsSteerAng: type=ADT_AbsSteerAng, direction=IN, server-argument-impl-policy=USE-ARGUMENT-TYPE
      Get_ActvRetFilFac
        arg FilFac_Val: type=ADT_FilFac_Val, direction=OUT, server-argument-impl-policy=USE-ARGUMENT-TYPE
      Get_ActvRetMotTrqGain
        arg MotTrqGain_Val: type=ADT_MotTrqGain_Val, direction=OUT, server-argument-impl-policy=USE-ARGUMENT-TYPE
        arg AbsAvgVehSpd: type=ADT_AbsAvgVehSpd, direction=IN, server-argument-impl-policy=USE-ARGUMENT-TYPE
      Get_ActvRetRetTrqFactDepOnDrvr
        arg RetTrqFactDepOnDrvr_Val: type=ADT_RetTrqFactDepOnDrvr_Val, direction=OUT, server-argument-impl-policy=USE-ARGUMENT-TYPE
        arg AbsDrvrTrq: type=ADT_AbsDrvrTrq, direction=IN, server-argument-impl-policy=USE-ARGUMENT-TYPE
        arg AbsAvgVehSpd: type=ADT_AbsAvgVehSpd, direction=IN, server-argument-impl-policy=USE-ARGUMENT-TYPE
      Get_ActvRetSteerSpdFactDepOnDrvr
        arg SteerSpdFactDepOnDrvr_Val: type=ADT_SteerSpdFactDepOnDrvr_Val, direction=OUT, server-argument-impl-policy=USE-ARGUMENT-TYPE
        arg AbsDrvrTrq: type=ADT_AbsDrvrTrq, direction=IN, server-argument-impl-policy=USE-ARGUMENT-TYPE
        arg AbsAvgVehSpd: type=ADT_AbsAvgVehSpd, direction=IN, server-argument-impl-policy=USE-ARGUMENT-TYPE
      Get_ActvRetSteerSpdGradAftInvld
        arg SteerSpdGradAftInvld_Val: type=ADT_SteerSpdGradAftInvld_Val, direction=OUT, server-argument-impl-policy=USE-ARGUMENT-TYPE
      Get_ActvRetSteerSpdAmp
        arg SteerSpdAmp_Val: type=ADT_SteerSpdAmp_Val, direction=OUT, server-argument-impl-policy=USE-ARGUMENT-TYPE
      Get_ActvRetSteerSpdFact
        arg SteerSpdFact_Val: type=ADT_SteerSpdFact_Val, direction=OUT, server-argument-impl-policy=USE-ARGUMENT-TYPE
      Get_ActvRetMaxMotTrqAftLoadFac
        arg MaxMotTrqAftLoadFac_Val: type=ADT_MaxMotTrqAftLoadFac_Val, direction=OUT, server-argument-impl-policy=USE-ARGUMENT-TYPE
package /Eps_Repository/ActiveReturn/ActiveReturnCdp/ConstantSpecification
  44 x constant specification:
    CS_MaxMotTrqDepOnSteerAng: value-spec=[0.5 0.5 0.5 0.5 0.5] NwtMtr
    CS_MaxMotTrqDepOnSteerAng_AxisX: value-spec=[0 100 200 300 500] DegAngle
    CS_MaxMotTrqDepOnVehSpd: value-spec=[0.5 0.5 0.5 0.5 0.5] NwtMtr
    CS_MaxMotTrqDepOnVehSpd_AxisX: value-spec=[0 10 40 90 100] KiloMtrPerHr
    CS_MaxMotTrq: value-spec=1 NwtMtr
    CS_MaxTBT4ShtDwn: value-spec=8 NwtMtr
    CS_NomSteerSpd: value-spec=[0 0 0 0 0 0 0 0 0 0 0 0 0 0 163.52 257.44 341.04 415.2 468.48 509.28 544.32 579.36 614.4 633.6 652.8 672 0 168.0622 264.5911 350.5133 426.7333 481.4933 523.4267 559.44 595.4533 631.4667 651.2 670.9333 690.6667 0 149.8933 235.9867 312.62 380.6 429.44 466.84 498.96 531.08 563.2 580.8 598.4 616 0 126.0467 198.4433 262.885 320.05 361.12 392.57 419.58 446.59 473.6 488.4 503.2 518 0 85.1667 134.0833 177.625 216.25 244 265.25 283.5 301.75 320 330 340 350] size 6x13
    CS_NomSteerSpd_AxisX: value-spec=[0 16 32 48 64 80] KiloMtrPerHr
    CS_NomSteerSpd_AxisY: value-spec=[0 16.6667 33.3333 50 66.6667 83.3333 100 116.6667 133.3333 150 166.6667 183.3333 200] DegAngle
    CS_FilFac: value-spec=0.1
    CS_MotTrqGain: value-spec=[0.8 0.87 1.03 1.22 1.31 1.5]
    CS_MotTrqGain_AxisX: value-spec=[0 10 50 120 150 230] KiloMtrPerHr
    CS_RetTrqFactDepOnDrvr: value-spec=[1 1 1 0.9 0.9 0.9 0.8 0.8 0.8 0.6 0.6 0.6 0.4 0.4 0.4 0.22 0.22 0.22] size 6x3
    CS_RetTrqFactDepOnDrvr_AxisX: value-spec=[0 0.5 1 2 3 4] NwtMtr
    CS_RetTrqFactDepOnDrvr_AxisY: value-spec=[0 60 120] KiloMtrPerHr
    CS_SteerSpdFactDepOnDrvr: value-spec=[1 1 1 0.9 0.9 0.9 0.8 0.8 0.8 0.6 0.6 0.6 0.4 0.4 0.4 0.22 0.22 0.22] size 6x3
    CS_SteerSpdFactDepOnDrvr_AxisX: value-spec=[0 0.5 1 2 3 4] NwtMtr
    CS_SteerSpdFactDepOnDrvr_AxisY: value-spec=[0 60 120] KiloMtrPerHr
    CS_SteerSpdGradAftInvld: value-spec=0.005
    CS_SteerSpdAmp: value-spec=0.003
    CS_SteerSpdFact: value-spec=1
    CS_MaxMotTrqDepOnSteerAng_AxisX_IDT: value-spec=[0.0, 1000, 2000, 3000, 5000]
    CS_MaxMotTrqDepOnSteerAng_IDT: value-spec=5 x 512
    CS_MaxMotTrqDepOnVehSpd_AxisX_IDT: value-spec=[0.0, 640, 2560, 5760, 6400]
    CS_MaxMotTrqDepOnVehSpd_IDT: value-spec=5 x 512
    CS_MotTrqGain_AxisX_IDT: value-spec=[0.0, 640, 3200, 7680, 9600, 14720]
    CS_MotTrqGain_IDT: value-spec=[819.2, 890.88, 1054.72, 1249.28, 1341.44, 1536.0]
    CS_RetTrqFactDepOnDrvr_AxisX_IDT: value-spec=[0.0, 512, 1024, 2048, 3072, 4096]
    CS_RetTrqFactDepOnDrvr_AxisY_IDT: value-spec=[0, 3840, 7680]
    CS_RetTrqFactDepOnDrvr_IDT: value-spec=[[1024, 1024, 1024], [921.6, 921.6, 921.6], [819.2, 819.2, 819.2], [614.4, 614.4, 614.4], [409.6, 409.6, 409.6], [225.28, 225.28, 225.28]]
    CS_SteerSpdFactDepOnDrvr_AxisX_IDT: value-spec=[0.0, 512, 1024, 2048, 3072, 4096]
    CS_SteerSpdFactDepOnDrvr_AxisY_IDT: value-spec=[0, 3840, 7680]
    CS_NomSteerSpd_AxisX_IDT: value-spec=[0.0, 1024, 2048, 3072, 4096, 5120]
    CS_NomSteerSpd_AxisY_IDT: value-spec=[0.0, 166.667, 333.333, 500, 666.667, 833.333, 1000, 1166.667, 1333.333, 1500, 1666.667, 1833.333, 2000]
    CS_SteerSpdFactDepOnDrvr_IDT: value-spec=[[1024, 1024, 1024], [921.6, 921.6, 921.6], [819.2, 819.2, 819.2], [614.4, 614.4, 614.4], [409.6, 409.6, 409.6], [225.28, 225.28, 225.28]]
    CS_FilFac_IDT: value-spec=[102.4]
    CS_SteerSpdFact_IDT: value-spec=[128]
    CS_SteerSpdGradAftInvld_IDT: value-spec=[163.84]
    CS_SteerSpdAmp_IDT: value-spec=[49.1520]
    CS_MaxMotTrq_IDT: value-spec=[64]
    CS_MaxTBT4ShtDwn_IDT: value-spec=[128]
    CS_NomSteerSpd_IDT: value-spec=[13 x 0, [0, 1308.16, 2059.52, 2728.32, 3321.6, 3747.84, 4074.24, 4354.56, 4634.88, 4915.2, 5068.8, 5222.4, 5376.0], [0, 1344.498, 2116.729, 2804.106, 3413.866, 3851.946, 4187.414, 4475.52, 4763.626, 5051.734, 5209.6, 5367.466, 5525.334], [0, 1199.146, 1887.894, 2500.96, 3044.8, 3435.52, 3734.72, 3991.68, 4248.64, 4505.6, 4646.4, 4787.2, 4928.0], [0, 1008.374, 1587.546, 2103.08, 2560.4, 2888.96, 3140.56, 3356.64, 3572.72, 3788.8, 3907.2, 4025.6, 4144.0], [0, 681.3336, 1072.666, 1421.0, 1730.0, 1952.0, 2122.0, 2268.0, 2414.05, 2560.0, 2640.0, 2720.0, 2800.0]]
    CS_MaxMotTrqAftLoadFac: value-spec=1
    CS_MaxMotTrqAftLoadFac_IDT: value-spec=[64]
package /Eps_Repository/ActiveReturn/ActiveReturnCdp/SwAddrMethods
  sw addr method CALIB: memory-allocation-keyword-policy=ADDR-METHOD-SHORT-NAME, section-type=CALPRM
package /Eps_Repository/ActiveReturn/ActiveReturnCdp/SwRecordLayouts
  sw record layout SwRecordLayout_Axis_uint16: sw-record-layout-group={short-label=X, category=INDEX_INCR, sw-record-layout-group-axis=1, sw-record-layout-group-from=1, sw-record-layout-group-to=-1, sw-record-layout-v={base-type=uint16, sw-record-layout-v-axis=1, sw-record-layout-v-prop=VALUE}}
  sw record layout SwRecordLayout_Curve_uint16: sw-record-layout-group={short-label=Val, category=COLUMN_DIR, sw-record-layout-group-axis=1, sw-record-layout-group-index=X, sw-record-layout-group-from=1, sw-record-layout-group-to=-1, sw-record-layout-v={base-type=uint16, sw-record-layout-v-axis=0, sw-record-layout-v-prop=VALUE, sw-record-layout-v-index=X}}
  sw record layout SwRecordLayout_Map_uint16: sw-record-layout-group={short-label=Val, category=COLUMN_DIR, sw-record-layout-group-axis=1, sw-record-layout-group-index=X, sw-record-layout-group-from=1, sw-record-layout-group-to=-1, sw-record-layout-group={sw-record-layout-group-axis=2, sw-record-layout-group-index=Y, sw-record-layout-group-from=1, sw-record-layout-group-to=-1, sw-record-layout-v={base-type=uint16, sw-record-layout-v-axis=0, sw-record-layout-v-prop=VALUE, sw-record-layout-v-index=X Y}}}
package /Eps_Repository/ActiveReturn/ActiveReturnCdp/ConstantSpecificationMappingSets
  constant specification mapping set CSMS_ActvRetCdp
    mappings:
      appl-constant=CS_MaxMotTrqDepOnSteerAng_AxisX, impl-constant=CS_MaxMotTrqDepOnSteerAng_AxisX_IDT
      appl-constant=CS_MaxMotTrqDepOnSteerAng, impl-constant=CS_MaxMotTrqDepOnSteerAng_IDT
      appl-constant=CS_MaxMotTrqDepOnVehSpd_AxisX, impl-constant=CS_MaxMotTrqDepOnVehSpd_AxisX_IDT
      appl-constant=CS_MaxMotTrqDepOnVehSpd, impl-constant=CS_MaxMotTrqDepOnVehSpd_IDT
      appl-constant=CS_MotTrqGain, impl-constant=CS_MotTrqGain_IDT
      appl-constant=CS_MotTrqGain_AxisX, impl-constant=CS_MotTrqGain_AxisX_IDT
      appl-constant=CS_RetTrqFactDepOnDrvr_AxisX, impl-constant=CS_RetTrqFactDepOnDrvr_AxisX_IDT
      appl-constant=CS_RetTrqFactDepOnDrvr_AxisY, impl-constant=CS_RetTrqFactDepOnDrvr_AxisY_IDT
      appl-constant=CS_RetTrqFactDepOnDrvr, impl-constant=CS_RetTrqFactDepOnDrvr_IDT
      appl-constant=CS_SteerSpdFactDepOnDrvr_AxisX, impl-constant=CS_SteerSpdFactDepOnDrvr_AxisX_IDT
      appl-constant=CS_SteerSpdFactDepOnDrvr_AxisY, impl-constant=CS_SteerSpdFactDepOnDrvr_AxisY_IDT
      appl-constant=CS_SteerSpdFactDepOnDrvr, impl-constant=CS_SteerSpdFactDepOnDrvr_IDT
      appl-constant=CS_MaxMotTrq, impl-constant=CS_MaxMotTrq_IDT
      appl-constant=CS_MaxTBT4ShtDwn, impl-constant=CS_MaxTBT4ShtDwn_IDT
      appl-constant=CS_FilFac, impl-constant=CS_FilFac_IDT
      appl-constant=CS_SteerSpdGradAftInvld, impl-constant=CS_SteerSpdGradAftInvld_IDT
      appl-constant=CS_SteerSpdAmp, impl-constant=CS_SteerSpdAmp_IDT
      appl-constant=CS_SteerSpdFact, impl-constant=CS_SteerSpdFact_IDT
      appl-constant=CS_NomSteerSpd, impl-constant=CS_NomSteerSpd_IDT
      appl-constant=CS_NomSteerSpd_AxisX, impl-constant=CS_NomSteerSpd_AxisX_IDT
      appl-constant=CS_NomSteerSpd_AxisY, impl-constant=CS_NomSteerSpd_AxisY_IDT
      appl-constant=CS_MaxMotTrqAftLoadFac, impl-constant=CS_MaxMotTrqAftLoadFac_IDT
